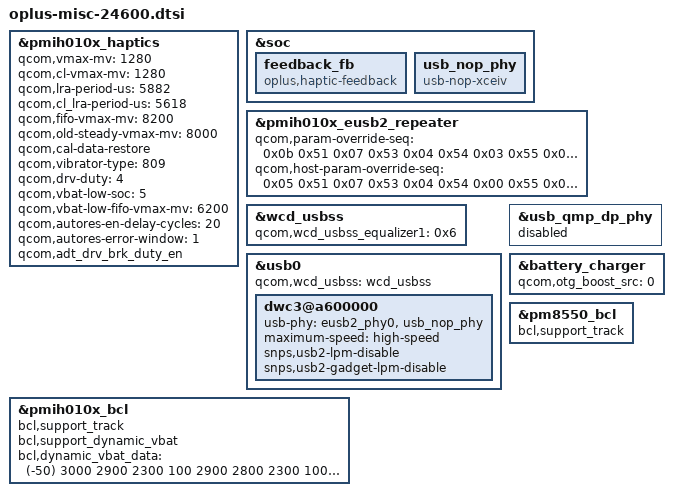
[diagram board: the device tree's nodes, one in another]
&pmih010x_haptics {
	qcom,vmax-mv = <1280>;
	qcom,cl-vmax-mv = <1280>;
	qcom,lra-period-us = <5882>;
	qcom,cl_lra-period-us = <5618>;
	qcom,fifo-vmax-mv = <8200>;
	qcom,old-steady-vmax-mv = <8000>;
	qcom,cal-data-restore;
	qcom,vibrator-type = <809>;//ela0809
	qcom,drv-duty = <4>;//75%
	qcom,vbat-low-soc = <5>;
	qcom,vbat-low-fifo-vmax-mv = <6200>;
	qcom,autores-en-delay-cycles = <20>; //10 cycle
	qcom,autores-error-window = <1>; //25 percent
	qcom,adt_drv_brk_duty_en;  //en f060 bit6 && bit7
};

&soc {
	feedback_fb: feedback_fb {
		compatible = "oplus,haptic-feedback";
	};
};

&pmih010x_eusb2_repeater {
	qcom,param-override-seq = <0x0b 0x51 0x07 0x53 0x04 0x54 0x03 0x55 0x03 0x57>;
	qcom,host-param-override-seq = <0x05 0x51 0x07 0x53 0x04 0x54 0x00 0x55 0x00 0x57>;
};

&wcd_usbss {
	qcom,wcd_usbss_equalizer1 = /bits/ 8 <0x6>;
};

&soc {
	usb_nop_phy: usb_nop_phy {
		compatible = "usb-nop-xceiv";
	};
};

&usb0 {
	qcom,wcd_usbss = <&wcd_usbss>;
	dwc3@a600000 {
		usb-phy = <&eusb2_phy0>, <&usb_nop_phy>;
		maximum-speed = "high-speed";
		snps,usb2-lpm-disable;
		snps,usb2-gadget-lpm-disable;
	};
};

&usb_qmp_dp_phy {
	status = "disabled";
};

&battery_charger {
	qcom,otg_boost_src = <0>; /* 0:plat_pmic 1:external */
};

&pmih010x_bcl {
	bcl,support_track;
	bcl,support_dynamic_vbat;
	bcl,dynamic_vbat_data = <(-50) 3000 2900 2300
				100 2900 2800 2300
				1000 2800 2600 2300>;
};

&pm8550_bcl {
	bcl,support_track;
};
